AUTOSAR XML (schema 4-2-2)
package /AUTOSAR_NvM/PortInterfaces
  6 x client server interface, all with is-service=true:
    NvMAdmin
      operation SetBlockProtection: possible-error=NvMAdmin/E_NOT_OK
        arg ProtectionEnabled: type=boolean, direction=IN
      error E_NOT_OK: error-code=1
    NvMMirror
      operation ReadRamBlockFromNvM: possible-error=NvMMirror/E_NOT_OK
        arg SrcPtr: type=NvM_Rb_VoidPtr, direction=IN
      operation WriteRamBlockToNvM: possible-error=NvMMirror/E_NOT_OK
        arg DstPtr: type=NvM_Rb_VoidPtr, direction=IN
      error E_NOT_OK: error-code=1
    NvMNotifyInitBlock
      operation InitBlock: possible-error=NvMNotifyInitBlock/E_NOT_OK
      error E_NOT_OK: error-code=1
    NvMNotifyJobFinished
      operation JobFinished: possible-error=NvMNotifyJobFinished/E_NOT_OK
        arg ServiceId: type=uint8, direction=IN
        arg JobResult: type=NvM_RequestResultType, direction=IN
      error E_NOT_OK: error-code=1
    NvMRbNotifyJobStarted
      operation JobStarted
        arg ServiceId: type=uint8, direction=IN
    NvMService
      12 x operation, all with possible-error=NvMService/E_NOT_OK:
        EraseBlock
        GetDataIndex
          arg DataIndexPtr: type=uint8, direction=OUT
        GetErrorStatus
          arg RequestResultPtr: type=NvM_RequestResultType, direction=OUT
        InvalidateNvBlock
        ReadBlock
          arg DstPtr: type=NvM_Rb_VoidPtr, direction=IN
        ReadPRAMBlock
        RestoreBlockDefaults
          arg DstPtr: type=NvM_Rb_VoidPtr, direction=IN
        RestorePRAMBlockDefaults
        SetDataIndex
          arg DataIndex: type=uint8, direction=IN
        SetRamBlockStatus
          arg BlockChanged: type=boolean, direction=IN
        WriteBlock
          arg SrcPtr: type=NvM_Rb_ConstVoidPtr, direction=IN
        WritePRAMBlock
      error E_NOT_OK: error-code=1
package /AUTOSAR_NvM/SwcImplementations
  swc implementation NvM: programming-language=C, swc-bsw-mapping=NvM, vendor-id=6, behavior=NVRAMManager
    code-descriptors:
      code CodeDescriptor: artifact-descriptors=autosar-engineering-object={short-label=ArEngObj, category=SWSRC}
package /AUTOSAR_NvM/SwComponentTypes
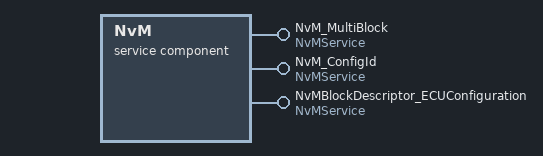
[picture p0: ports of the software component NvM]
  service sw component type NvM
    provide port NvM_MultiBlock: provided-interface=NvMService
      provided-com-specs:
        operation=EraseBlock, queue-length=1
        operation=GetDataIndex, queue-length=1
        operation=GetErrorStatus, queue-length=1
        operation=InvalidateNvBlock, queue-length=1
        operation=ReadBlock, queue-length=1
        operation=ReadPRAMBlock, queue-length=1
        operation=RestoreBlockDefaults, queue-length=1
        operation=RestorePRAMBlockDefaults, queue-length=1
        operation=SetDataIndex, queue-length=1
        operation=SetRamBlockStatus, queue-length=1
        operation=WriteBlock, queue-length=1
        operation=WritePRAMBlock, queue-length=1
    provide port NvM_ConfigId: provided-interface=NvMService
      provided-com-specs:
        operation=EraseBlock, queue-length=1
        operation=GetDataIndex, queue-length=1
        operation=GetErrorStatus, queue-length=1
        operation=InvalidateNvBlock, queue-length=1
        operation=ReadBlock, queue-length=1
        operation=ReadPRAMBlock, queue-length=1
        operation=RestoreBlockDefaults, queue-length=1
        operation=RestorePRAMBlockDefaults, queue-length=1
        operation=SetDataIndex, queue-length=1
        operation=SetRamBlockStatus, queue-length=1
        operation=WriteBlock, queue-length=1
        operation=WritePRAMBlock, queue-length=1
    provide port NvMBlockDescriptor_ECUConfiguration: provided-interface=NvMService
      provided-com-specs:
        operation=EraseBlock, queue-length=1
        operation=GetDataIndex, queue-length=1
        operation=GetErrorStatus, queue-length=1
        operation=InvalidateNvBlock, queue-length=1
        operation=ReadBlock, queue-length=1
        operation=ReadPRAMBlock, queue-length=1
        operation=RestoreBlockDefaults, queue-length=1
        operation=RestorePRAMBlockDefaults, queue-length=1
        operation=SetDataIndex, queue-length=1
        operation=SetRamBlockStatus, queue-length=1
        operation=WriteBlock, queue-length=1
        operation=WritePRAMBlock, queue-length=1
    behavior NVRAMManager
      36 x operation invoked event:
        EENB_NvM_MultiBlock: start-on-event=EraseNvBlock, operation=NvM_MultiBlock.EraseBlock
        EGDI_NvM_MultiBlock: start-on-event=GetDataIndex, operation=NvM_MultiBlock.GetDataIndex
        EGES_NvM_MultiBlock: start-on-event=GetErrorStatus, operation=NvM_MultiBlock.GetErrorStatus
        EINB_NvM_MultiBlock: start-on-event=InvalidateNvBlock, operation=NvM_MultiBlock.InvalidateNvBlock
        ERBL_NvM_MultiBlock: start-on-event=ReadBlock, operation=NvM_MultiBlock.ReadBlock
        ERPBL_NvM_MultiBlock: start-on-event=ReadPRAMBlock, operation=NvM_MultiBlock.ReadPRAMBlock
        ERBD_NvM_MultiBlock: start-on-event=RestoreBlockDefaults, operation=NvM_MultiBlock.RestoreBlockDefaults
        ERPBD_NvM_MultiBlock: start-on-event=RestorePRAMBlockDefaults, operation=NvM_MultiBlock.RestorePRAMBlockDefaults
        ESDI_NvM_MultiBlock: start-on-event=SetDataIndex, operation=NvM_MultiBlock.SetDataIndex
        ESRS_NvM_MultiBlock: start-on-event=SetRamBlockStatus, operation=NvM_MultiBlock.SetRamBlockStatus
        EWBL_NvM_MultiBlock: start-on-event=WriteBlock, operation=NvM_MultiBlock.WriteBlock
        EWPBL_NvM_MultiBlock: start-on-event=WritePRAMBlock, operation=NvM_MultiBlock.WritePRAMBlock
        EENB_NvM_ConfigId: start-on-event=EraseNvBlock, operation=NvM_ConfigId.EraseBlock
        EGDI_NvM_ConfigId: start-on-event=GetDataIndex, operation=NvM_ConfigId.GetDataIndex
        EGES_NvM_ConfigId: start-on-event=GetErrorStatus, operation=NvM_ConfigId.GetErrorStatus
        EINB_NvM_ConfigId: start-on-event=InvalidateNvBlock, operation=NvM_ConfigId.InvalidateNvBlock
        ERBL_NvM_ConfigId: start-on-event=ReadBlock, operation=NvM_ConfigId.ReadBlock
        ERPBL_NvM_ConfigId: start-on-event=ReadPRAMBlock, operation=NvM_ConfigId.ReadPRAMBlock
        ERBD_NvM_ConfigId: start-on-event=RestoreBlockDefaults, operation=NvM_ConfigId.RestoreBlockDefaults
        ERPBD_NvM_ConfigId: start-on-event=RestorePRAMBlockDefaults, operation=NvM_ConfigId.RestorePRAMBlockDefaults
        ESDI_NvM_ConfigId: start-on-event=SetDataIndex, operation=NvM_ConfigId.SetDataIndex
        ESRS_NvM_ConfigId: start-on-event=SetRamBlockStatus, operation=NvM_ConfigId.SetRamBlockStatus
        EWBL_NvM_ConfigId: start-on-event=WriteBlock, operation=NvM_ConfigId.WriteBlock
        EWPBL_NvM_ConfigId: start-on-event=WritePRAMBlock, operation=NvM_ConfigId.WritePRAMBlock
        EENB_NvMBlockDescriptor_ECUConfiguration: start-on-event=EraseNvBlock, operation=NvMBlockDescriptor_ECUConfiguration.EraseBlock
        EGDI_NvMBlockDescriptor_ECUConfiguration: start-on-event=GetDataIndex, operation=NvMBlockDescriptor_ECUConfiguration.GetDataIndex
        EGES_NvMBlockDescriptor_ECUConfiguration: start-on-event=GetErrorStatus, operation=NvMBlockDescriptor_ECUConfiguration.GetErrorStatus
        EINB_NvMBlockDescriptor_ECUConfiguration: start-on-event=InvalidateNvBlock, operation=NvMBlockDescriptor_ECUConfiguration.InvalidateNvBlock
        ERBL_NvMBlockDescriptor_ECUConfiguration: start-on-event=ReadBlock, operation=NvMBlockDescriptor_ECUConfiguration.ReadBlock
        ERPBL_NvMBlockDescriptor_ECUConfiguration: start-on-event=ReadPRAMBlock, operation=NvMBlockDescriptor_ECUConfiguration.ReadPRAMBlock
        ERBD_NvMBlockDescriptor_ECUConfiguration: start-on-event=RestoreBlockDefaults, operation=NvMBlockDescriptor_ECUConfiguration.RestoreBlockDefaults
        ERPBD_NvMBlockDescriptor_ECUConfiguration: start-on-event=RestorePRAMBlockDefaults, operation=NvMBlockDescriptor_ECUConfiguration.RestorePRAMBlockDefaults
        ESDI_NvMBlockDescriptor_ECUConfiguration: start-on-event=SetDataIndex, operation=NvMBlockDescriptor_ECUConfiguration.SetDataIndex
        ESRS_NvMBlockDescriptor_ECUConfiguration: start-on-event=SetRamBlockStatus, operation=NvMBlockDescriptor_ECUConfiguration.SetRamBlockStatus
        EWBL_NvMBlockDescriptor_ECUConfiguration: start-on-event=WriteBlock, operation=NvMBlockDescriptor_ECUConfiguration.WriteBlock
        EWPBL_NvMBlockDescriptor_ECUConfiguration: start-on-event=WritePRAMBlock, operation=NvMBlockDescriptor_ECUConfiguration.WritePRAMBlock
      port-api-options:
        {enable-take-address=false, indirect-api=false, port-defined-argument-value{value=0, value-type=NvM_BlockIdType}, port=NvM_MultiBlock}
        {enable-take-address=false, indirect-api=false, port-defined-argument-value{value=1, value-type=NvM_BlockIdType}, port=NvM_ConfigId}
        {enable-take-address=false, indirect-api=false, port-defined-argument-value{value=15, value-type=NvM_BlockIdType}, port=NvMBlockDescriptor_ECUConfiguration}
      14 x runnable:
        EraseNvBlock: runnable-entity-argument=symbol=BlockId, can-be-invoked-concurrently=true, symbol=NvM_EraseNvBlock
        GetDataIndex: arguments=[symbol=BlockId, symbol=DataIndexPtr], can-be-invoked-concurrently=true, symbol=NvM_GetDataIndex
        GetErrorStatus: arguments=[symbol=BlockId, symbol=RequestResultPtr], can-be-invoked-concurrently=true, symbol=NvM_GetErrorStatus
        InvalidateNvBlock: runnable-entity-argument=symbol=BlockId, can-be-invoked-concurrently=true, symbol=NvM_InvalidateNvBlock
        ReadBlock: arguments=[symbol=BlockId, symbol=NvM_DstPtr], can-be-invoked-concurrently=true, symbol=NvM_ReadBlock
        ReadPRAMBlock: runnable-entity-argument=symbol=BlockId, can-be-invoked-concurrently=true, symbol=NvM_ReadPRAMBlock
        RestoreBlockDefaults: arguments=[symbol=BlockId, symbol=NvM_DstPtr], can-be-invoked-concurrently=true, symbol=NvM_RestoreBlockDefaults
        RestorePRAMBlockDefaults: runnable-entity-argument=symbol=BlockId, can-be-invoked-concurrently=true, symbol=NvM_RestorePRAMBlockDefaults
        SetBlockProtection: arguments=[symbol=BlockId, symbol=ProtectionEnabled], can-be-invoked-concurrently=true, symbol=NvM_SetBlockProtection
        SetDataIndex: arguments=[symbol=BlockId, symbol=DataIndex], can-be-invoked-concurrently=true, symbol=NvM_SetDataIndex
        SetRamBlockStatus: arguments=[symbol=BlockId, symbol=BlockChanged], can-be-invoked-concurrently=true, symbol=NvM_SetRamBlockStatus
        WriteBlock: arguments=[symbol=BlockId, symbol=NvM_SrcPtr], can-be-invoked-concurrently=true, symbol=NvM_WriteBlock
        WritePRAMBlock: runnable-entity-argument=symbol=BlockId, can-be-invoked-concurrently=true, symbol=NvM_WritePRAMBlock
        MainFunction: symbol=NvM_MainFunction
